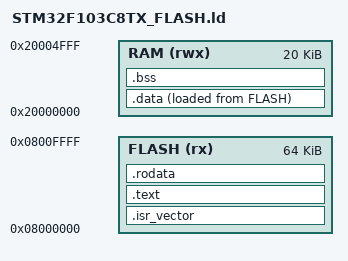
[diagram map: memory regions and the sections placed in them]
MEMORY
{
    FLASH (rx)  : ORIGIN = 0x08000000, LENGTH = 64K
    RAM   (rwx) : ORIGIN = 0x20000000, LENGTH = 20K
}

ENTRY(Reset_Handler)

SECTIONS
{
    .isr_vector :
    {
        KEEP(*(.isr_vector))
    } > FLASH

    .text :
    {
        . = ALIGN(4);
        *(.text)
        *(.text*)
        *(.glue_7)
        *(.glue_7t)
        KEEP(*(.init))
        KEEP(*(.fini))
        . = ALIGN(4);
        _etext = .;
    } > FLASH

    .rodata :
    {
        . = ALIGN(4);
        *(.rodata)
        *(.rodata*)
        . = ALIGN(4);
    } > FLASH

    .data :
    {
        . = ALIGN(4);
        _sdata = .;
        *(.data)
        *(.data*)
        . = ALIGN(4);
        _edata = .;
    } > RAM AT > FLASH

    _sidata = LOADADDR(.data);

    .bss :
    {
        . = ALIGN(4);
        _sbss = .;
        *(.bss)
        *(.bss*)
        *(COMMON)
        . = ALIGN(4);
        _ebss = .;
    } > RAM

    /* Top of stack, grows down from end of RAM */
    _estack = ORIGIN(RAM) + LENGTH(RAM);
}
